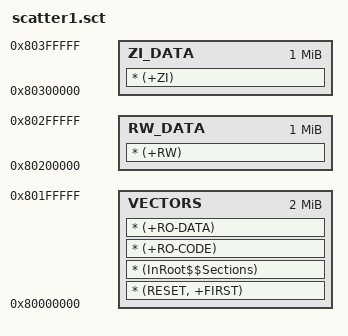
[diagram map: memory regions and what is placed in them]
;**************************************************
; Copyright (c) 2013 ARM Ltd.  All rights reserved.
; Modified by yqhuang@uwaterloo.ca for ECE350 LAB
;**************************************************

; Scatter-file for RTX on Versatile Express

; This scatter-file places application code, data, stack and heap at suitable addresses in the memory map.

; This platform has 2GB SDRAM starting at 0x80000000.

;#include "mem_ARMCA9.h"

SDRAM 0x80000000 0x40000000
{
    VECTORS +0 0x200000
    {
        * (RESET, +FIRST)         ; Vector table and other (assembler) startup code
        * (InRoot$$Sections)      ; All (library) code that must be in a root region
        * (+RO-CODE)              ; Application RO code (.text)
        * (+RO-DATA)              ; Application RO data (.constdata)
    }

    RW_DATA 0x80200000 0x100000
    { * (+RW) }                   ; Application RW data (.data)

    ZI_DATA 0x80300000 0x100000
    { * (+ZI) }                   ; Application ZI data (.bss)
}
